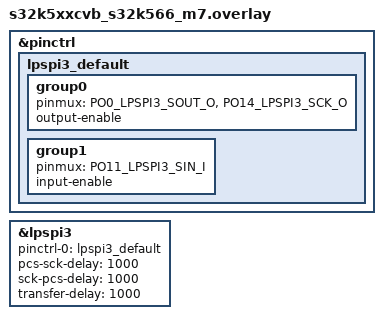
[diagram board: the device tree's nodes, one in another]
/*
 * Copyright 2025 NXP
 *
 * SPDX-License-Identifier: Apache-2.0
 */

&pinctrl {
	lpspi3_default: lpspi3_default {
		group0 {
			pinmux = <PO0_LPSPI3_SOUT_O>, <PO14_LPSPI3_SCK_O>;
			output-enable;
		};

		group1 {
			pinmux = <PO11_LPSPI3_SIN_I>;
			input-enable;
		};
	};
};

#define SPI_LOOPBACK_FAST_HZ 5000000

spi_loopback: &lpspi3 {
	status = "okay";
	pinctrl-0 = <&lpspi3_default>;
	pinctrl-names = "default";
	pcs-sck-delay = <1000>;
	sck-pcs-delay = <1000>;
	transfer-delay = <1000>;
};

#include "../spi-loopback.dtsi"
